# ATSAMD11D14AU register map
Vendor: Microchip Technology; Series: SAMD11; File version: 0
CPU: CM0+ r0p0, little endian, no MPU, no FPU, VTOR, 2 interrupt priority bits, 19 interrupts
Registers are 32-bit, read-write, reset 0x0 unless marked. A register's access mark holds for its fields unless they carry their own. Offsets are from the block's base; [hi:lo] are bit positions; lines under a group give offsets from that group; {n}, {i} and the like mark numbered series; 'fields as' and 'values as' point back to an identical list.

## PAC0 — Peripheral Access Controller
Base 0x40000000; register names take the prefix PAC_
Same registers: PAC1 0x41000000, PAC2 0x42000000
0x00 WPCLR write-1-clears — Write Protection Clear
  [31:1] WP
0x04 WPSET write-1-sets — Write Protection Set
  [31:1] WP

## PM — Power Manager
Base 0x40000400
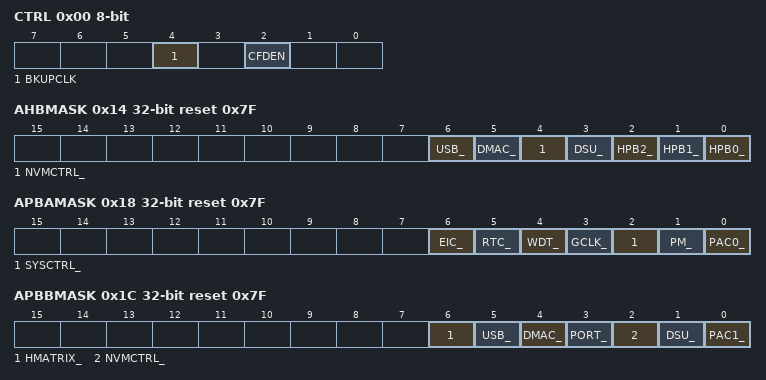
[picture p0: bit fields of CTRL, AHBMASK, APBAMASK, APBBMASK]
0x00 CTRL 8-bit — Control
  [4] BKUPCLK — Backup Clock Select
  [2] CFDEN — Clock Failure Detector Enable
0x01 SLEEP 8-bit — Sleep Mode
  [1:0] IDLE — Idle Mode Configuration
    0=CPU (The CPU clock domain is stopped); 1=AHB (The CPU and AHB clock domains are stopped); 2=APB (The CPU, AHB and APB clock domains are stopped)
0x02 EXTCTRL 8-bit — External Reset Controller
  [0] SETDIS — External Reset Disable
0x08 CPUSEL 8-bit — CPU Clock Select
  [2:0] CPUDIV — CPU Prescaler Selection
    0=DIV1 (Divide by 1); 1=DIV2 (Divide by 2); 2=DIV4 (Divide by 4); 3=DIV8 (Divide by 8); 4=DIV16 (Divide by 16); 5=DIV32 (Divide by 32); 6=DIV64 (Divide by 64); 7=DIV128 (Divide by 128)
0x09 APBASEL 8-bit — APBA Clock Select
  [2:0] APBADIV — APBA Prescaler Selection
    values as CPUSEL.CPUDIV
0x0A APBBSEL 8-bit — APBB Clock Select
  [2:0] APBBDIV — APBB Prescaler Selection
    values as CPUSEL.CPUDIV
0x0B APBCSEL 8-bit — APBC Clock Select
  [2:0] APBCDIV — APBC Prescaler Selection
    values as CPUSEL.CPUDIV
0x14 AHBMASK reset 0x7F
  [6] USB_ — USB AHB Clock Mask
  [5] DMAC_ — DMAC AHB Clock Mask
  [4] NVMCTRL_ — NVMCTRL AHB Clock Mask
  [3] DSU_ — DSU AHB Clock Mask
  [2] HPB2_ — HPB2 AHB Clock Mask
  [1] HPB1_ — HPB1 AHB Clock Mask
  [0] HPB0_ — HPB0 AHB Clock Mask
0x18 APBAMASK reset 0x7F
  [6] EIC_ — EIC APB Clock Enable
  [5] RTC_ — RTC APB Clock Enable
  [4] WDT_ — WDT APB Clock Enable
  [3] GCLK_ — GCLK APB Clock Enable
  [2] SYSCTRL_ — SYSCTRL APB Clock Enable
  [1] PM_ — PM APB Clock Enable
  [0] PAC0_ — PAC0 APB Clock Enable
0x1C APBBMASK reset 0x7F
  [6] HMATRIX_ — HMATRIX APB Clock Enable
  [5] USB_ — USB APB Clock Enable
  [4] DMAC_ — DMAC APB Clock Enable
  [3] PORT_ — PORT APB Clock Enable
  [2] NVMCTRL_ — NVMCTRL APB Clock Enable
  [1] DSU_ — DSU APB Clock Enable
  [0] PAC1_ — PAC1 APB Clock Enable
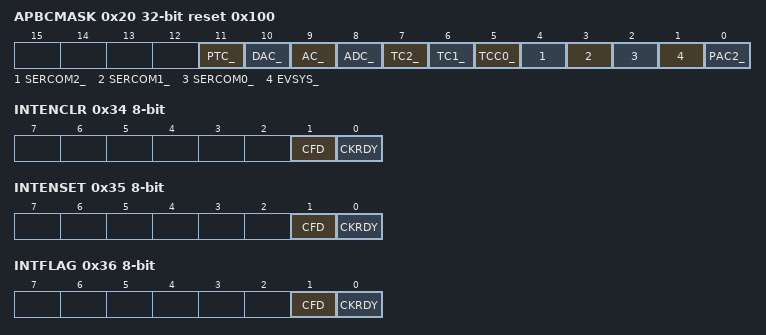
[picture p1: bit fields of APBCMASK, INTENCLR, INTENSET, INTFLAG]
0x20 APBCMASK reset 0x100
  [11] PTC_ — PTC APB Clock Enable
  [10] DAC_ — DAC APB Clock Enable
  [9] AC_ — AC APB Clock Enable
  [8] ADC_ — ADC APB Clock Enable
  [7] TC2_ — TC2 APB Clock Enable
  [6] TC1_ — TC1 APB Clock Enable
  [5] TCC0_ — TCC0 APB Clock Enable
  [4] SERCOM2_ — SERCOM2 APB Clock Enable
  [3] SERCOM1_ — SERCOM1 APB Clock Enable
  [2] SERCOM0_ — SERCOM0 APB Clock Enable
  [1] EVSYS_ — EVSYS APB Clock Enable
  [0] PAC2_ — PAC2 APB Clock Enable
0x34 INTENCLR 8-bit write-1-clears — Interrupt Enable Clear
  [1] CFD — Clock Failure Detector Interrupt Enable
  [0] CKRDY — Clock Ready Interrupt Enable
0x35 INTENSET 8-bit write-1-sets — Interrupt Enable Set
  fields as INTENCLR
0x36 INTFLAG 8-bit write-1-clears — Interrupt Flag Status and Clear
  [1] CFD — Clock Failure Detector
  [0] CKRDY — Clock Ready
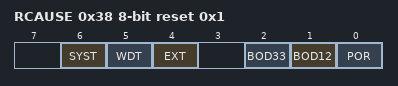
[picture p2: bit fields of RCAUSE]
0x38 RCAUSE 8-bit ro reset 0x1 — Reset Cause
  [6] SYST — System Reset Request
  [5] WDT — Watchdog Reset
  [4] EXT — External Reset
  [2] BOD33 — Brown Out 33 Detector Reset
  [1] BOD12 — Brown Out 12 Detector Reset
  [0] POR — Power On Reset

## PORT — Port Module
Base 0x41004400
Same registers: PORT_IOBUS 0x60000000
{0x0+0x80*i} GROUP[{i}] (i=0..0) group
  0x00 DIR — Data Direction
    [31:0] DIR — Port Data Direction
  0x04 DIRCLR — Data Direction Clear
    [31:0] DIRCLR — Port Data Direction Clear
  0x08 DIRSET — Data Direction Set
    [31:0] DIRSET — Port Data Direction Set
  0x0C DIRTGL — Data Direction Toggle
    [31:0] DIRTGL — Port Data Direction Toggle
  0x10 OUT — Data Output Value
    [31:0] OUT — Port Data Output Value
  0x14 OUTCLR — Data Output Value Clear
    [31:0] OUTCLR — Port Data Output Value Clear
  0x18 OUTSET — Data Output Value Set
    [31:0] OUTSET — Port Data Output Value Set
  0x1C OUTTGL — Data Output Value Toggle
    [31:0] OUTTGL — Port Data Output Value Toggle
  0x20 IN ro — Data Input Value
    [31:0] IN — Port Data Input Value
  0x24 CTRL — Control
    [31:0] SAMPLING — Input Sampling Mode
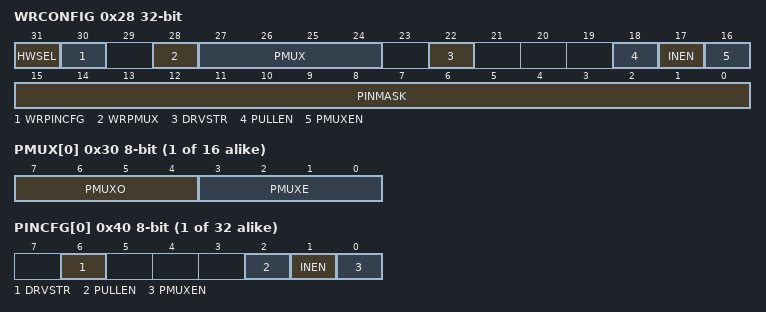
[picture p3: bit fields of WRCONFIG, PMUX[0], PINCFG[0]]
  0x28 WRCONFIG wo — Write Configuration
    [31] HWSEL — Half-Word Select
    [30] WRPINCFG — Write PINCFG
    [28] WRPMUX — Write PMUX
    [27:24] PMUX — Peripheral Multiplexing
    [22] DRVSTR — Output Driver Strength Selection
    [18] PULLEN — Pull Enable
    [17] INEN — Input Enable
    [16] PMUXEN — Peripheral Multiplexer Enable
    [15:0] PINMASK — Pin Mask for Multiple Pin Configuration
  {0x30+j} PMUX[{j}] (j=0..15) 8-bit — Peripheral Multiplexing n
    [7:4] PMUXO — Peripheral Multiplexing Odd
      0=A (Peripheral function A selected); 1=B (Peripheral function B selected); 2=C (Peripheral function C selected); 3=D (Peripheral function D selected); 4=E (Peripheral function E selected); 5=F (Peripheral function F selected); 6=G (Peripheral function G selected); 7=H (Peripheral function H selected)
    [3:0] PMUXE — Peripheral Multiplexing Even
      values as PMUXO
  {0x40+j} PINCFG[{j}] (j=0..31) 8-bit — Pin Configuration n
    [6] DRVSTR — Output Driver Strength Selection
    [2] PULLEN — Pull Enable
    [1] INEN — Input Enable
    [0] PMUXEN — Peripheral Multiplexer Enable
